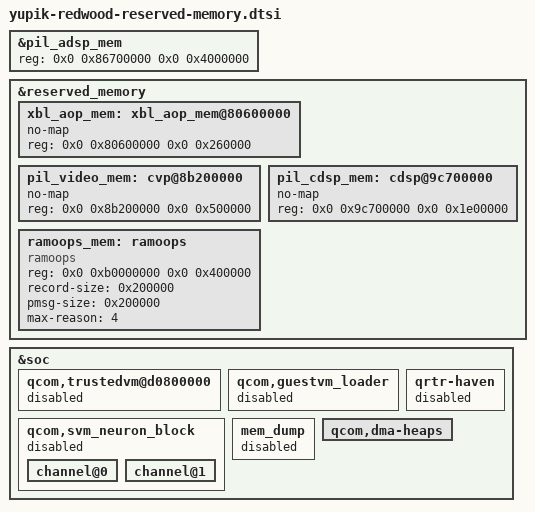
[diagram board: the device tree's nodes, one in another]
// SPDX-License-Identifier: BSD-3-Clause

/*
 * Reserved memory as redwood's firmware lays it out, which differs from
 * the later yupik firmware that yupik.dtsi describes.
 */

/delete-node/ &xbl_aop_mem;
/delete-node/ &video_mem;
/delete-node/ &pil_cdsp_mem;

&pil_adsp_mem {
	reg = <0x0 0x86700000 0x0 0x4000000>;
};

&reserved_memory {
	xbl_aop_mem: xbl_aop_mem@80600000 {
		no-map;
		reg = <0x0 0x80600000 0x0 0x260000>;
	};

	pil_video_mem: cvp@8b200000 {
		no-map;
		reg = <0x0 0x8b200000 0x0 0x500000>;
	};

	pil_cdsp_mem: cdsp@9c700000 {
		no-map;
		reg = <0x0 0x9c700000 0x0 0x1e00000>;
	};
};

/* No trusted VM on redwood, its carveouts are RAM for Linux */
/delete-node/ &pil_trustedvm_mem;
/delete-node/ &qrtr_shbuf;
/delete-node/ &chan0_shbuf;
/delete-node/ &chan1_shbuf;

&soc {
	qcom,trustedvm@d0800000 {
		/delete-property/ memory-region;
		status = "disabled";
	};

	qcom,guestvm_loader {
		status = "disabled";
	};

	qcom,svm_neuron_block {
		status = "disabled";

		channel@0 {
			/delete-property/ shared-buffer;
		};

		channel@1 {
			/delete-property/ shared-buffer;
		};
	};

	qrtr-haven {
		/delete-property/ shared-buffer;
		status = "disabled";
	};
};

/* The same static ramoops as the 5.4 kernel, so either kernel reads the other's record */
/delete-node/ &ramoops_mem;

&reserved_memory {
	ramoops_mem: ramoops {
		compatible = "ramoops";
		reg = <0x0 0xb0000000 0x0 0x400000>;
		record-size = <0x200000>;
		pmsg-size = <0x200000>;
		max-reason = <4>;
	};
};

&soc {
	/delete-node/ qcom_ramoops;
};

/* Regions for drivers this kernel doesn't build, none of them reserved on the phone */
/delete-node/ &kinfo_mem;
/delete-node/ &va_md_mem;
/delete-node/ &dump_mem;
/delete-node/ &non_secure_display_memory;

&soc {
	/delete-node/ google,debug-kinfo;
	/delete-node/ va_mini_dump;

	mem_dump {
		/delete-property/ memory-region;
		status = "disabled";
	};

	qcom,dma-heaps {
		/delete-node/ qcom,display;
	};
};
